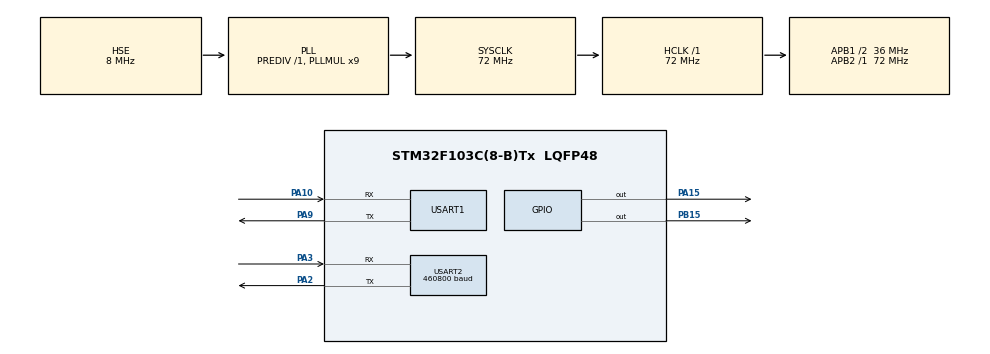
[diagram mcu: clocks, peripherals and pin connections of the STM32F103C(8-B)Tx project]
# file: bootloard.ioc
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Mcu.Family=STM32F1
Mcu.Name=STM32F103C(8-B)Tx
Mcu.Package=LQFP48
NVIC.PriorityGroup=NVIC_PRIORITYGROUP_4
PA10.Mode=Asynchronous
PA10.Signal=USART1_RX
PA13.Mode=Serial_Wire
PA13.Signal=SYS_JTMS-SWDIO
PA14.Mode=Serial_Wire
PA14.Signal=SYS_JTCK-SWCLK
PA15.Signal=GPIO_Output
PA2.Mode=Asynchronous
PA2.Signal=USART2_TX
PA3.Mode=Asynchronous
PA3.Signal=USART2_RX
PA9.Mode=Asynchronous
PA9.Signal=USART1_TX
PB15.Signal=GPIO_Output
PD0-OSC_IN.Mode=HSE-External-Oscillator
PD0-OSC_IN.Signal=RCC_OSC_IN
PD1-OSC_OUT.Mode=HSE-External-Oscillator
PD1-OSC_OUT.Signal=RCC_OSC_OUT
ProjectManager.HeapSize=0x200
ProjectManager.StackSize=0x400
ProjectManager.TargetToolchain=MDK-ARM V5.32
RCC.AHBFreq_Value=72000000
RCC.APB1CLKDivider=RCC_HCLK_DIV2
RCC.APB1Freq_Value=36000000
RCC.APB1TimFreq_Value=72000000
RCC.APB2Freq_Value=72000000
RCC.APB2TimFreq_Value=72000000
RCC.HCLKFreq_Value=72000000
RCC.PLLMUL=RCC_PLL_MUL9
RCC.PLLSourceVirtual=RCC_PLLSOURCE_HSE
RCC.SYSCLKFreq_VALUE=72000000
RCC.SYSCLKSource=RCC_SYSCLKSOURCE_PLLCLK
RCC.USBFreq_Value=72000000
USART1.VirtualMode=VM_ASYNC
USART2.BaudRate=460800
USART2.VirtualMode=VM_ASYNC
board=custom

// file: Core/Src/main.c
/* USER CODE BEGIN Header */
/******************************************************************************
 *  文件名称        : main.c
 *  作者            : 青山
 *  创建日期        : 2025-11-25
 *  最后修改日期    :
 *  文件描述        : bootloader引导加载程序
 *
 *  ----------------------------------------------------------------------------
 *  修改记录:
 *  日期           作者        版本号     修改内容
 *  2025-11-25    青山         1.0.0      初始创建
 *
 ******************************************************************************/
/******************************************************************************
 *  Bootloader / 应用程序 地址布局说明
 *
 *  Flash 地址分布（基于 64KB Flash 的 STM32F103C8T6）：
 *
 *  ┌───────────────────────────────────────────────────────────────┐
 *  │  Bootloader 区域（16 KB）                                     │
 *  │  地址：0x08000000 ~ 0x08003FFF                                │
 *  └───────────────────────────────────────────────────────────────┘
 *
 *  ┌───────────────────────────────────────────────────────────────┐
 *  │  升级标志区 + 版本号（1 KB）                                    │
 *  │  地址：0x08004000 ~ 0x080043FF                                │
 *  │  - upgrade_flag (需要升级则写入 0x01)                          │
 *  │  - firmware_version (如 0x00010000 → V1.0.0)                  │
 *  └───────────────────────────────────────────────────────────────┘
 *
 *  ┌───────────────────────────────────────────────────────────────┐
 *  │  应用程序区域（约 47 KB）                                       │
 *  │  地址：0x08004400 ~ 0x0800FFFF                                 │
 *  └───────────────────────────────────────────────────────────────┘
 *
 *  Bootloader 跳转逻辑：
 *  1. 上电 → Bootloader 启动
 *  2. 读取 0x08004000 的 upgrade_flag
 *  3. 如果 upgrade_flag == 1：
 *       → 进入 OTA/ESP8266 升级流程
 *     否则：
 *       → 跳转到应用程序 (0x08004400)
 *
 ******************************************************************************/

/* USER CODE END Header */
#include "main.h"
#include "usart.h"
#include "gpio.h"

/* USER CODE BEGIN Includes */
#include "my_log.h"
#include "bootloard.h"
/* USER CODE END Includes */

/* USER CODE BEGIN PD */
       //application 起始地址
/* USER CODE END PD */

/* USER CODE BEGIN PV */
extern upgrade_info_t g_upgrade_info;
/* USER CODE END PV */

void SystemClock_Config(void);

int main(void)
{

  /* MCU Configuration--------------------------------------------------------*/

  /* Reset of all peripherals, Initializes the Flash interface and the Systick. */
  HAL_Init();

  /* Configure the system clock */
  SystemClock_Config();

  /* Initialize all configured peripherals */
  MX_GPIO_Init();
  MX_USART1_UART_Init();
  MX_USART2_UART_Init();
  /* USER CODE BEGIN 2 */
	log_init(&huart1);

  CheckVersion();
//  LOG_INFO("Version:%d.%d", g_upgrade_info.h_version, g_upgrade_info.l_version);

  if(g_upgrade_info.upgrade_flag == 0xaaaaaaaa)
  {
    LOG_INFO("Ready to start updating......");
		FirmwareUpdate();

    ClearUpgradeFlag();
    LOG_INFO("Update Version:%d.%d", g_upgrade_info.h_version, g_upgrade_info.l_version);
		goto_application();
  }else
  {
    LOG_INFO("Jump to Application......");
    goto_application();
  }

  /* USER CODE END 2 */

  /* Infinite loop */
  while (1)
  {

  }
}

void SystemClock_Config(void)
{
  RCC_OscInitTypeDef RCC_OscInitStruct = {0};
  RCC_ClkInitTypeDef RCC_ClkInitStruct = {0};

  /** Initializes the RCC Oscillators according to the specified parameters
  * in the RCC_OscInitTypeDef structure.
  */
  RCC_OscInitStruct.OscillatorType = RCC_OSCILLATORTYPE_HSE;
  RCC_OscInitStruct.HSEState = RCC_HSE_ON;
  RCC_OscInitStruct.HSEPredivValue = RCC_HSE_PREDIV_DIV1;
  RCC_OscInitStruct.HSIState = RCC_HSI_ON;
  RCC_OscInitStruct.PLL.PLLState = RCC_PLL_ON;
  RCC_OscInitStruct.PLL.PLLSource = RCC_PLLSOURCE_HSE;
  RCC_OscInitStruct.PLL.PLLMUL = RCC_PLL_MUL9;
  if (HAL_RCC_OscConfig(&RCC_OscInitStruct) != HAL_OK)
  {
    Error_Handler();
  }

  /** Initializes the CPU, AHB and APB buses clocks
  */
  RCC_ClkInitStruct.ClockType = RCC_CLOCKTYPE_HCLK|RCC_CLOCKTYPE_SYSCLK
                              |RCC_CLOCKTYPE_PCLK1|RCC_CLOCKTYPE_PCLK2;
  RCC_ClkInitStruct.SYSCLKSource = RCC_SYSCLKSOURCE_PLLCLK;
  RCC_ClkInitStruct.AHBCLKDivider = RCC_SYSCLK_DIV1;
  RCC_ClkInitStruct.APB1CLKDivider = RCC_HCLK_DIV2;
  RCC_ClkInitStruct.APB2CLKDivider = RCC_HCLK_DIV1;

  if (HAL_RCC_ClockConfig(&RCC_ClkInitStruct, FLASH_LATENCY_2) != HAL_OK)
  {
    Error_Handler();
  }
}

void Error_Handler(void)
{
  __disable_irq();
  while (1)
  {
  }
}
